AUTOSAR XML (schema 00046)
package /Runnables_Lab2
  sender receiver interface SRI_Output
    data SumResult: type=uint32
  sender receiver interface SRI_Input
    data Val1: type=uint16
    data Val2: type=uint16
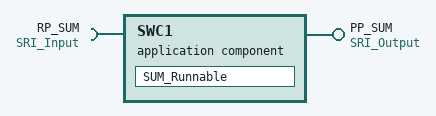
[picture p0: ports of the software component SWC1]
  application sw component type SWC1
    provide port PP_SUM: provided-interface=SRI_Output
    require port RP_SUM: required-interface=SRI_Input
    behavior SWC1_Behavior
      runnable SUM_Runnable: symbol=SUM
        data-read-access:
          access Val1_Data: accessed-variable=RP_SUM.Val1
          access Val2_Data: accessed-variable=RP_SUM.Val2
        data-write-access:
          access SumResult_Data: accessed-variable=PP_SUM.SumResult
